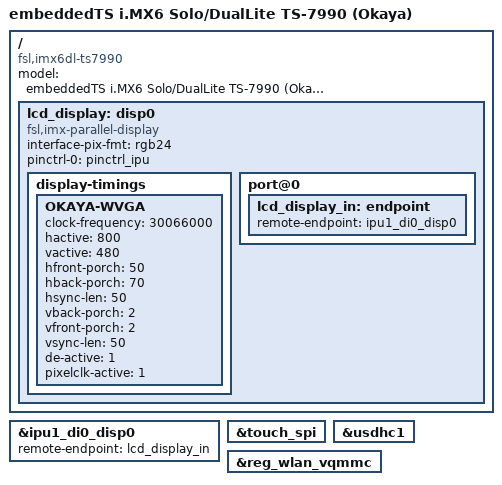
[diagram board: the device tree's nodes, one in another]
// SPDX-License-Identifier: GPL-2.0 OR X11
/*
 * Copyright 2017-2022 Technologic Systems, Inc. dba embeddedTS
 */

/dts-v1/;
#include "imx6dl.dtsi"
#include "imx6qdl-ts7990.dtsi"

/ {
	model = "embeddedTS i.MX6 Solo/DualLite TS-7990 (Okaya)";
	compatible = "fsl,imx6dl-ts7990", "fsl,imx6dl";

	lcd_display: disp0 {
		compatible = "fsl,imx-parallel-display";
		#address-cells = <1>;
		#size-cells = <0>;
		interface-pix-fmt = "rgb24";
		pinctrl-names = "default";
		pinctrl-0 = <&pinctrl_ipu>;

		display-timings {
			OKAYA-WVGA {
				clock-frequency = <30066000>;
				hactive = <800>;
				vactive = <480>;
				hfront-porch = <50>;
				hback-porch = <70>;
				hsync-len = <50>;
				vback-porch = <2>;
				vfront-porch = <2>;
				vsync-len = <50>;

				de-active = <1>;
				pixelclk-active = <1>;
			};
		};

		port@0 {
			lcd_display_in: endpoint {
				remote-endpoint = <&ipu1_di0_disp0>;
			};
		};
	};
};

&ipu1_di0_disp0 {
	remote-endpoint = <&lcd_display_in>;
};

&touch_spi {
	status = "okay";
};

&usdhc1 {
	status = "okay";
};

&reg_wlan_vqmmc {
	status = "okay";
};
